AUTOSAR XML (schema 00046)
package /IOA_SWC_1_package
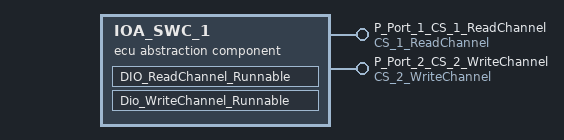
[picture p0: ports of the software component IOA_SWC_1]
  ecu abstraction sw component type IOA_SWC_1
    provide port P_Port_1_CS_1_ReadChannel: server-com-spec=CS_1_ReadChannel_Operation1, provided-interface=CS_1_ReadChannel
    provide port P_Port_2_CS_2_WriteChannel: server-com-spec=CS_2_WriteChannel_Operation_1, provided-interface=CS_2_WriteChannel
    behavior IOA_SWC_1_internal_behavior
      operation invoked event Operation_Invoked_Event_1_event: start-on-event=DIO_ReadChannel_Runnable, operation=P_Port_1_CS_1_ReadChannel.CS_1_ReadChannel_Operation1
      operation invoked event Operation_Invoked_Event_2_event: start-on-event=Dio_WriteChannel_Runnable, operation=P_Port_2_CS_2_WriteChannel.CS_2_WriteChannel_Operation_1
      runnable DIO_ReadChannel_Runnable: symbol=IOA_SWC_DIO_ReadChannel_Runnable
      runnable Dio_WriteChannel_Runnable: symbol=IOA_SWC_Dio_WriteChannel_Runnable
